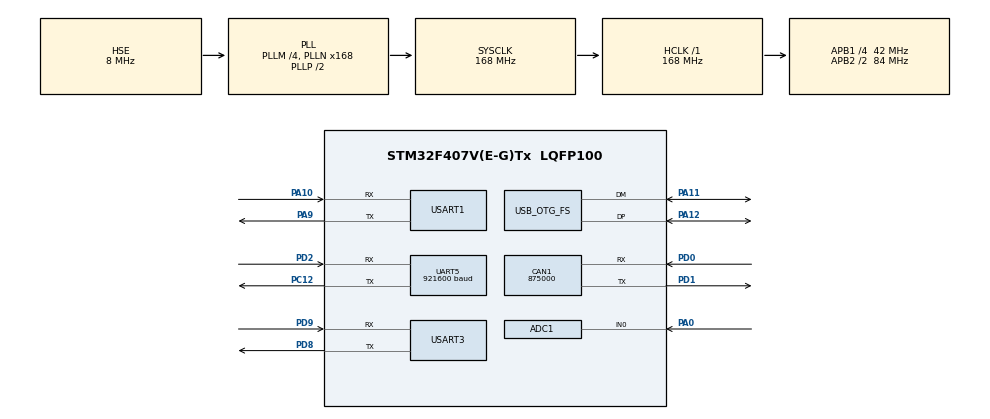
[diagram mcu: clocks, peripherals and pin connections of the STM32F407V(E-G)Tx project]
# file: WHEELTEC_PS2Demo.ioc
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ADC1.Channel-2\#ChannelRegularConversion=ADC_CHANNEL_0
ADC1.ContinuousConvMode=ENABLE
ADC1.NbrOfConversionFlag=1
ADC1.Rank-2\#ChannelRegularConversion=1
ADC1.SamplingTime-2\#ChannelRegularConversion=ADC_SAMPLETIME_3CYCLES
ADC1.master=1
CAN1.CalculateBaudRate=875000
CAN1.CalculateTimeBit=1142
CAN1.CalculateTimeQuantum=380.95238095238096
Dma.Request0=UART5_RX
Dma.UART5_RX.0.Direction=DMA_PERIPH_TO_MEMORY
Dma.UART5_RX.0.FIFOMode=DMA_FIFOMODE_DISABLE
Dma.UART5_RX.0.Instance=DMA1_Stream0
Dma.UART5_RX.0.MemDataAlignment=DMA_MDATAALIGN_BYTE
Dma.UART5_RX.0.MemInc=DMA_MINC_ENABLE
Dma.UART5_RX.0.Mode=DMA_CIRCULAR
Dma.UART5_RX.0.PeriphDataAlignment=DMA_PDATAALIGN_BYTE
Dma.UART5_RX.0.PeriphInc=DMA_PINC_DISABLE
Dma.UART5_RX.0.Priority=DMA_PRIORITY_HIGH
Mcu.Family=STM32F4
Mcu.Name=STM32F407V(E-G)Tx
Mcu.Package=LQFP100
NVIC.DMA1_Stream0_IRQn=true\:0\:0\:false\:false\:true\:false\:true\:true
NVIC.OTG_FS_IRQn=true\:0\:0\:false\:false\:true\:false\:true\:true
NVIC.PriorityGroup=NVIC_PRIORITYGROUP_4
NVIC.UART5_IRQn=true\:0\:0\:false\:false\:true\:true\:true\:true
NVIC.USART1_IRQn=true\:0\:0\:false\:false\:true\:true\:true\:true
NVIC.USART3_IRQn=true\:0\:0\:false\:false\:true\:true\:true\:true
PA0-WKUP.Signal=ADCx_IN0
PA10.Mode=Asynchronous
PA10.Signal=USART1_RX
PA11.Mode=Host_Only
PA11.Signal=USB_OTG_FS_DM
PA12.Mode=Host_Only
PA12.Signal=USB_OTG_FS_DP
PA13.Mode=Serial_Wire
PA13.Signal=SYS_JTMS-SWDIO
PA14.Mode=Serial_Wire
PA14.Signal=SYS_JTCK-SWCLK
PA9.Mode=Asynchronous
PA9.Signal=USART1_TX
PC12.Mode=Asynchronous
PC12.Signal=UART5_TX
PD0.Mode=CAN_Activate
PD0.Signal=CAN1_RX
PD1.Mode=CAN_Activate
PD1.Signal=CAN1_TX
PD2.Mode=Asynchronous
PD2.Signal=UART5_RX
PD8.Mode=Asynchronous
PD8.Signal=USART3_TX
PD9.Mode=Asynchronous
PD9.Signal=USART3_RX
PH0-OSC_IN.Mode=HSE-External-Oscillator
PH0-OSC_IN.Signal=RCC_OSC_IN
PH1-OSC_OUT.Mode=HSE-External-Oscillator
PH1-OSC_OUT.Signal=RCC_OSC_OUT
ProjectManager.HeapSize=0x200
ProjectManager.StackSize=0x400
ProjectManager.TargetToolchain=MDK-ARM V5.32
RCC.48MHZClocksFreq_Value=48000000
RCC.AHBFreq_Value=168000000
RCC.APB1CLKDivider=RCC_HCLK_DIV4
RCC.APB1Freq_Value=42000000
RCC.APB1TimFreq_Value=84000000
RCC.APB2CLKDivider=RCC_HCLK_DIV2
RCC.APB2Freq_Value=84000000
RCC.APB2TimFreq_Value=168000000
RCC.CortexFreq_Value=168000000
RCC.HCLKFreq_Value=168000000
RCC.HSE_VALUE=8000000
RCC.HSI_VALUE=16000000
RCC.LSE_VALUE=32768
RCC.PLLM=4
RCC.PLLN=168
RCC.PLLQ=7
RCC.SYSCLKFreq_VALUE=168000000
RCC.SYSCLKSource=RCC_SYSCLKSOURCE_PLLCLK
RCC.VCOOutputFreq_Value=336000000
SH.ADCx_IN0.0=ADC1_IN0,IN0
UART5.BaudRate=921600
UART5.VirtualMode=Asynchronous
USART1.VirtualMode=VM_ASYNC
USART3.VirtualMode=VM_ASYNC
USB_HOST.SW_VBUS_DRIVE_HID_FS=true
USB_HOST.USBH_DEBUG_LEVEL-HID_FS=3
USB_HOST.USBH_HandleTypeDef-HID_FS=hUsbHostFS
USB_HOST.USBH_MAX_DATA_BUFFER-HID_FS=1024
USB_HOST.USBH_MAX_NUM_SUPPORTED_CLASS-HID_FS=4
USB_HOST.VirtualModeFS=Hid
USB_OTG_FS.VirtualMode=Host_Only
USB_OTG_FS.phy_itface=HCD_PHY_EMBEDDED
VP_USB_HOST_VS_USB_HOST_HID_FS.Mode=HID_FS
board=custom

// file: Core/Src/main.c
/* USER CODE BEGIN Header */
/**
 ******************************************************************************
 * @file           : main.c
 * @brief          : Main program body
 ******************************************************************************
 * @attention      :
 *
 * Copyright (c) 2025 STMicroelectronics.
 * All rights reserved.
 *
 * This software is licensed under terms that can be found in the LICENSE file
 * in the root directory of this software component.
 * If no LICENSE file comes with this software, it is provided AS-IS.
 *
 ******************************************************************************
 */
/* USER CODE END Header */
#include "main.h"
#include "adc.h"
#include "can.h"
#include "dma.h"
#include "usart.h"
#include "usb_host.h"
#include "gpio.h"

/* USER CODE BEGIN Includes */
#include "other.h"
#include "HWT906.h"
#include "bsp_ps2.h"

#include "dm_motor_drv.h"
#include "bsp_can.h"
#include "dm_motor_ctrl.h"

/* USER CODE END Includes */

void SystemClock_Config(void);
void MX_USB_HOST_Process(void);

int main(void)
{

  /* MCU Configuration--------------------------------------------------------*/

  /* Reset of all peripherals, Initializes the Flash interface and the Systick. */
  HAL_Init();

  /* Configure the system clock */
  SystemClock_Config();

  /* Initialize all configured peripherals */
  MX_GPIO_Init();
  MX_DMA_Init();
  MX_USART1_UART_Init();
  MX_USB_HOST_Init();
  MX_USART3_UART_Init();
  MX_CAN1_Init();
  MX_UART5_Init();
  MX_ADC1_Init();
  /* USER CODE BEGIN 2 */
  HWT906_Init();
  Menu_Init();
  // 测试printf是否工作
  printf("System Init OK\r\n");

  /* USER CODE END 2 */

  /* Infinite loop */
  while (1)
  {
    MX_USB_HOST_Process();

    /* USER CODE BEGIN 3 */
    Process_Command();
    /* USER CODE END 3 */
  }
}
void SystemClock_Config(void)
{
  RCC_OscInitTypeDef RCC_OscInitStruct = {0};
  RCC_ClkInitTypeDef RCC_ClkInitStruct = {0};

  /** Configure the main internal regulator output voltage
   */
  __HAL_RCC_PWR_CLK_ENABLE();
  __HAL_PWR_VOLTAGESCALING_CONFIG(PWR_REGULATOR_VOLTAGE_SCALE1);

  /** Initializes the RCC Oscillators according to the specified parameters
   * in the RCC_OscInitTypeDef structure.
   */
  RCC_OscInitStruct.OscillatorType = RCC_OSCILLATORTYPE_HSE;
  RCC_OscInitStruct.HSEState = RCC_HSE_ON;
  RCC_OscInitStruct.PLL.PLLState = RCC_PLL_ON;
  RCC_OscInitStruct.PLL.PLLSource = RCC_PLLSOURCE_HSE;
  RCC_OscInitStruct.PLL.PLLM = 4;
  RCC_OscInitStruct.PLL.PLLN = 168;
  RCC_OscInitStruct.PLL.PLLP = RCC_PLLP_DIV2;
  RCC_OscInitStruct.PLL.PLLQ = 7;
  if (HAL_RCC_OscConfig(&RCC_OscInitStruct) != HAL_OK)
  {
    Error_Handler();
  }

  /** Initializes the CPU, AHB and APB buses clocks
   */
  RCC_ClkInitStruct.ClockType = RCC_CLOCKTYPE_HCLK | RCC_CLOCKTYPE_SYSCLK | RCC_CLOCKTYPE_PCLK1 | RCC_CLOCKTYPE_PCLK2;
  RCC_ClkInitStruct.SYSCLKSource = RCC_SYSCLKSOURCE_PLLCLK;
  RCC_ClkInitStruct.AHBCLKDivider = RCC_SYSCLK_DIV1;
  RCC_ClkInitStruct.APB1CLKDivider = RCC_HCLK_DIV4;
  RCC_ClkInitStruct.APB2CLKDivider = RCC_HCLK_DIV2;

  if (HAL_RCC_ClockConfig(&RCC_ClkInitStruct, FLASH_LATENCY_5) != HAL_OK)
  {
    Error_Handler();
  }
}

void Error_Handler(void)
{
  __disable_irq();
  while (1)
  {
  }
}
